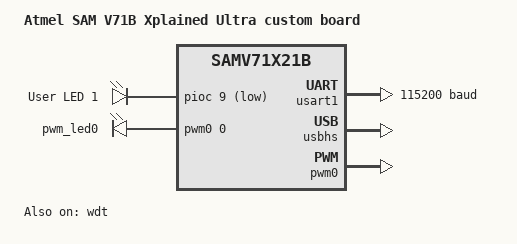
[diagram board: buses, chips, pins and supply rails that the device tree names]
/*
 * Copyright (c) 2026 Enzo Donadel <enzo.donadel95@gmail.com>
 *
 * SPDX-License-Identifier: Apache-2.0
 */

/dts-v1/;
#include <atmel/samv71x21b.dtsi>
#include "scratch_board-pinctrl.dtsi"
#include <zephyr/dt-bindings/input/input-event-codes.h>

/ {
	model = "Atmel SAM V71B Xplained Ultra custom board";
	compatible = "custom,scratch_board";
	
	aliases {
		led0 = &yellow_led1;
		pwm-led0 = &pwm_led0;
		watchdog0 = &wdt;
	};
	
	chosen {
		zephyr,console = &usart1;
		zephyr,shell-uart = &usart1;
		zephyr,sram = &sram0;
		zephyr,flash = &flash0;
		zephyr,code-partition = &slot0_partition;
	};

	leds {
		compatible = "gpio-leds";

		yellow_led0: led_0 {
			gpios = <&pioa 23 GPIO_ACTIVE_LOW>;
			label = "User LED 0";
			status = "disabled";
		};

		yellow_led1: led_1 {
			gpios = <&pioc 9 GPIO_ACTIVE_LOW>;
			label = "User LED 1";
			status = "okay";
		};
	};

	pwmleds {
		compatible = "pwm-leds";

		pwm_led0: pwm_led_0 {
			pwms = <&pwm0 0 PWM_MSEC(20) PWM_POLARITY_INVERTED>;
		};
	};
};

&usart1 {
	status = "okay";
	current-speed = <115200>;

	pinctrl-0 = <&usart1_default>;
	pinctrl-names = "default";
};

&cpu0 {
	clock-frequency = <300000000>;
};

zephyr_udc0: &usbhs {
	status = "okay";
};
&pioa {
	status = "okay";
};

&pioc {
	status = "okay";
};
&pwm0 {
	status = "okay";

	pinctrl-0 = <&pwm_default>;
	pinctrl-names = "default";
};
&flash0 {
	partitions {
		compatible = "fixed-partitions";
		#address-cells = <1>;
		#size-cells = <1>;

		/*
		 * The first half of sector 0 (64 kbytes)
		 * is reserved for the bootloader
		 */
		boot_partition: partition@0 {
			label = "mcuboot";
			reg = <0x0 0x00010000>;
			read-only;
		};

		/* From sector 1 to sector 15 (included): slot0 */
		slot0_partition: partition@20000 {
			label = "image-0";
			reg = <0x00020000 0x001e0000>;
		};
	};
};

&wdt {
	status = "okay";
};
